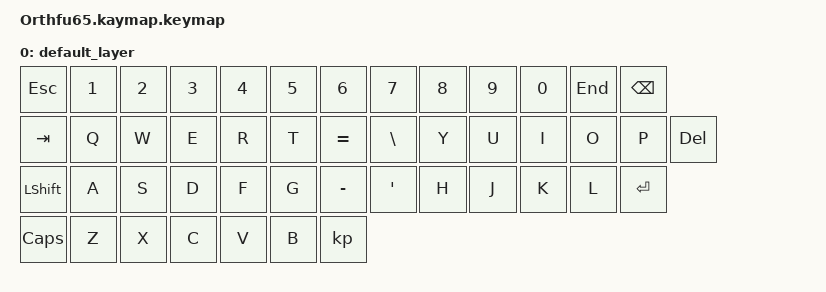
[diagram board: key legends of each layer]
/*
 * Copyright (c) 2022 The ZMK Contributors
 *
 * SPDX-License-Identifier: MIT
 */

#include <behaviors.dtsi>
#include <dt-bindings/zmk/keys.h>
#include <dt-bindings/zmk/bt.h>

#define DEFAULT 0
#define LOWER 1

/ {
    keymap {
        compatible = "zmk,keymap";

    default_layer {
// ---------------------------------------------------------------------------------------------------------------------------
//                       |  ESC |  1  |  2  |  3   |  4   |  5   |  6   |  7   |  8   |  9    |  0    | END  |   BACKSPACE   |
//                       |  TAB |  Q  |  W  |  E   |  R   |  T   |  =   |  \   |  Y   |  U    |  I    |  O   |   P   |   DEL |
//     |  BLANK |  BLANK |LSHIFT|  A  |  S  |  D   |  F   |  G   |  -   |  '   |  H   |  J    |  K    |  L   |     ENTER     |
//     |  BLANK |  BLANK | CAPS |  Z  |  X  |  C   |  V   |  B   |  ;   |  /   |  N   |  M    |  ,    |  .   |   UP  |RSHIFT |
//     |  BLANK |  BLANK | CTRL |BLANK| WIN | LALT |  FN  |   SPACE1    |    SPACE2   | RALT  | RCTRL | LEFT | DOWN  | RIGHT | 

            bindings = <
                        &kp ESC     &kp 1     &kp 2   &kp 3    &kp 4    &kp 5  &kp 6  &kp 7    &kp 8    &kp 9     &kp 0     &kp END     &kp BACKSPACE
                        &kp TAB     &kp Q     &kp W   &kp E    &kp R    &kp T  &kp =  &kp \    &kp Y    &kp U     &kp I     &kp O     &kp P    &kp DEL
                        &kp LSHIFT  &kp A     &kp S   &kp D    &kp F    &kp G  &kp -  &kp '    &kp H    &kp J     &kp K     &kp L       &kp ENTER
                        &kp CAPS    &kp Z     &kp X   &kp C    &kp V    &kp B  &kp ;  &kp /    &kp N    &kp M     &kp ,     &kp .     &kp UP   &kp RSHFT
                        &kp CTRL    &kp BLANK &kp WIN &kp LALT &kp FN   &kp SPACE1       &kp SPACE2     &kp RALT  &kp RCTRL &kp LEFT  &kp DOWN kp RIGHT
            >;
        };
    };
};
